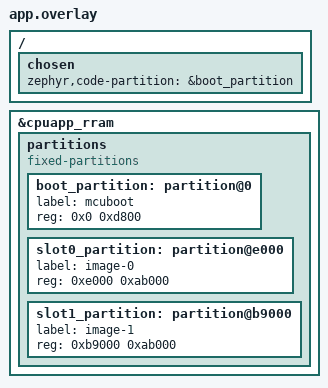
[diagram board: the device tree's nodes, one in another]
/ {
	chosen {
		zephyr,code-partition = &boot_partition;
	};
};

/* 先删除 SDK 默认的 partitions 节点（绝对路径） */
/delete-node/ &{/soc/rram-controller@5004b000/rram@0/partitions};

/* 重新定义整个分区表 */
&cpuapp_rram {
    partitions {
        compatible = "fixed-partitions";
        #address-cells = <1>;
        #size-cells = <1>;

        boot_partition: partition@0 {
            label = "mcuboot";
            reg = <0x0 0xd800>;
        };

        slot0_partition: partition@e000 {
            label = "image-0";
            reg = <0xe000 0xab000>;
        };

        slot1_partition: partition@b9000 {
            label = "image-1";
            reg = <0xb9000 0xab000>;
        };
    };
};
